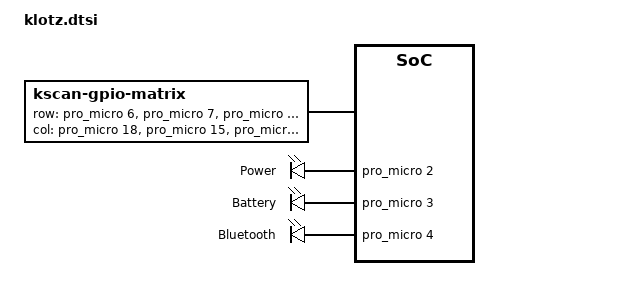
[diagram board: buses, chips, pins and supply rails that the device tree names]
/ {
    // ... (manten lo de chosen y default_transform igual)

    kscan0: kscan {
        compatible = "zmk,kscan-gpio-matrix";
        label = "KSCAN";
        diode-direction = "col2row";
        row-gpios
            = <&pro_micro 6 (GPIO_ACTIVE_HIGH | GPIO_PULL_DOWN)>
            , <&pro_micro 7 (GPIO_ACTIVE_HIGH | GPIO_PULL_DOWN)>
            , <&pro_micro 8 (GPIO_ACTIVE_HIGH | GPIO_PULL_DOWN)>
            , <&pro_micro 9 (GPIO_ACTIVE_HIGH | GPIO_PULL_DOWN)>
            ;
        // Verifica que estos pines coincidan con el esquema de tu Klotz
        col-gpios
            = <&pro_micro 18 GPIO_ACTIVE_HIGH>
            , <&pro_micro 15 GPIO_ACTIVE_HIGH>
            , <&pro_micro 14 GPIO_ACTIVE_HIGH>
            , <&pro_micro 16 GPIO_ACTIVE_HIGH>
            , <&pro_micro 10 GPIO_ACTIVE_HIGH>
            ;
    };

    // Para que los LEDs enciendan, los definimos como "indicadores de estado"
    leds {
        compatible = "gpio-leds";
        led_pwr: led_0 {
            gpios = <&pro_micro 2 GPIO_ACTIVE_HIGH>;
            label = "Power";
        };
        led_bat: led_1 {
            gpios = <&pro_micro 3 GPIO_ACTIVE_HIGH>;
            label = "Battery";
        };
        led_bt: led_2 {
            gpios = <&pro_micro 4 GPIO_ACTIVE_HIGH>;
            label = "Bluetooth";
        };
    };
};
